# STM32H730xxQ register map
File version: 1.0
Registers are 32-bit, read-write, reset 0x0 unless marked. A register's access mark holds for its fields unless they carry their own. Offsets are from the block's base; [hi:lo] are bit positions.

## PWR — Power Control
Base 0x58024800
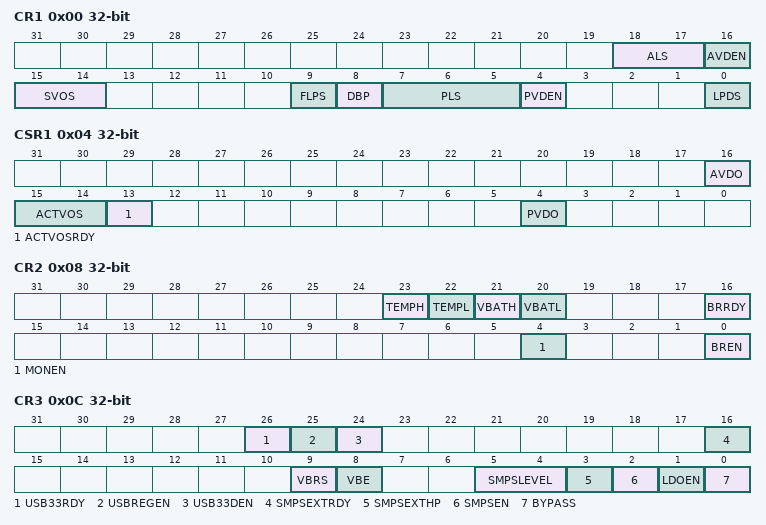
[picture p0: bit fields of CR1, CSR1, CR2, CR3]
0x00 CR1 — PWR power control register 1
  [18:17] ALS — Analog Voltage Detector level selection
    0=AVDLEVEL_0 (Analog Voltage threshold detected by AVD 1.7 V); 1=AVDLEVEL_1 (Analog Voltage threshold detected by AVD 2.1 V); 2=AVDLEVEL_2 (Analog Voltage threshold detected by AVD 2.5 V); 3=AVDLEVEL_3 (Analog Voltage threshold detected by AVD 2.8 V)
  [16] AVDEN — Analog Voltage Detector Enable
  [15:14] SVOS — System STOP mode Voltage Scaling selection
    3=SCALE3 (Select voltage scale 3 when system enters STOP mode); 2=SCALE4 (Select voltage scale 4 when system enters STOP mode); 1=SCALE5 (Select voltage scale 5 when system enters STOP mode)
  [9] FLPS — Flash low power mode in DSTOP
  [8] DBP — Disable Back-up domain Protection
  [7:5] PLS — Programmable Voltage Detector level selection
    0=PVDLEVEL_0 (Voltage threshold detected by PVD 1.95 V); 1=PVDLEVEL_1 (Voltage threshold detected by PVD 2.1 V); 2=PVDLEVEL_2 (Voltage threshold detected by PVD 2.25 V); 3=PVDLEVEL_3 (Voltage threshold detected by PVD 2.4 V); 4=PVDLEVEL_4 (Voltage threshold detected by PVD 2.55 V); 5=PVDLEVEL_5 (Voltage threshold detected by PVD 2.7 V); 6=PVDLEVEL_6 (Voltage threshold detected by PVD 2.85 V); 7=PVDLEVEL_7 (External voltage level on PVD_IN pin, compared to internal VREFINT level.)
  [4] PVDEN — Programmable Voltage detector enable
  [0] LPDS — Low Power Deepsleep with SVOS3
    0=MAIN (Voltage Regulator in main mode during deepsleep mode); 1=LOW_POWER (Voltage Regulator in low-power mode during deepsleep mode)
0x04 CSR1 — PWR power control status register 1
  [16] AVDO — Analog Voltage Detect Output
  [15:14] ACTVOS — Current actual used VOS for VDD11 Voltage Scaling
  [13] ACTVOSRDY — Ready bit for current actual used VOS for VDD11 Voltage Scaling
  [4] PVDO — Programmable Voltage Detect Output
0x08 CR2 — PWR power control register 2
  [23] TEMPH — Monitored temperature level above high threshold
  [22] TEMPL — Monitored temperature level above low threshold
  [21] VBATH — Monitored VBAT level above high threshold
  [20] VBATL — Monitored VBAT level above low threshold
  [16] BRRDY — Backup regulator ready
  [4] MONEN — VBAT and temperature monitoring enable
  [0] BREN — Backup regulator enable
0x0C CR3 — PWR power control register 3
  [26] USB33RDY — USB supply ready
  [25] USBREGEN — USB regulator enable
  [24] USB33DEN — VDD33_USB voltage level detector enable
  [16] SMPSEXTRDY — SMPS External supply ready
  [9] VBRS — VBAT charging resistor selection
    0=CHARG_RESISTOR_5K (Charge the Battery through a 5 kO resistor); 1=CHARGRESISTOR_1_5K (Charge the Battery through a 1.5 kO resistor)
  [8] VBE — VBAT charging enable
  [5:4] SMPSLEVEL — SMPS output Voltage
  [3] SMPSEXTHP — SMPS forced ON and in High Power MR mode
  [2] SMPSEN — SMPS Enable
  [1] LDOEN — Low Drop Output regulator enable
  [0] BYPASS — Power Management Unit bypass
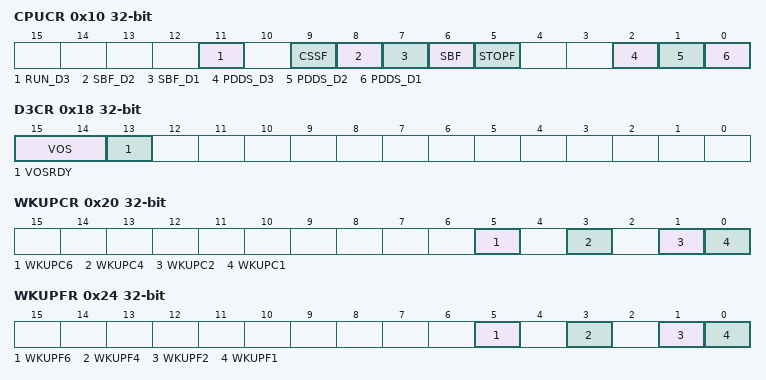
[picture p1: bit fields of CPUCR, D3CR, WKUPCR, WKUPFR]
0x10 CPUCR — PWR CPU control register
  [11] RUN_D3 — Keep system D3 domain in RUN mode regardless of the CPU sub-systems modes
  [9] CSSF — Clear D1 domain CPU1 STANDBY, STOP and HOLD flags
  [8] SBF_D2 — D2 domain DSTANDBY Flag
  [7] SBF_D1 — D1 domain DSTANDBY Flag
  [6] SBF — System STANDBY Flag
  [5] STOPF — STOP Flag
  [2] PDDS_D3 — System D3 domain Power Down Deepsleep
    0=D3STOP (Enter D3 domain to Stop mode when the CPU enters deepsleep); 1=D3STANDBY (Enter D3 domain to Standby mode when the CPU enters deepsleep)
  [1] PDDS_D2 — D2 domain Power Down Deepsleep
    0=D2STOP (Enter D2 domain to Stop mode when the CPU enters deepsleep); 1=D2STANDBY (Enter D2 domain to Standby mode when the CPU enters deepsleep)
  [0] PDDS_D1 — D1 domain Power Down Deepsleep selection
    0=D1STOP (Enter D1 domain to Stop mode when the CPU enters deepsleep); 1=D1STANDBY (Enter D1 domain to Standby mode when the CPU enters deepsleep)
0x18 D3CR — PWR D3 domain control register
  [15:14] VOS — Voltage Scaling selection according performance
  [13] VOSRDY — VOS Ready bit for VDD11 Voltage Scaling output selection
0x20 WKUPCR — PWR wakeup clear register
  [5] WKUPC6 — Clear Wakeup Pin Flag 6
  [3] WKUPC4 — Clear Wakeup Pin Flag 4
  [1] WKUPC2 — Clear Wakeup Pin Flag 2
  [0] WKUPC1 — Clear Wakeup Pin Flag 1
0x24 WKUPFR — PWR wakeup flag register
  [5] WKUPF6 — Wakeup Pin Flag 6
  [3] WKUPF4 — Wakeup Pin Flag 4
  [1] WKUPF2 — Wakeup Pin Flag 2
  [0] WKUPF1 — Wakeup Pin Flag 1
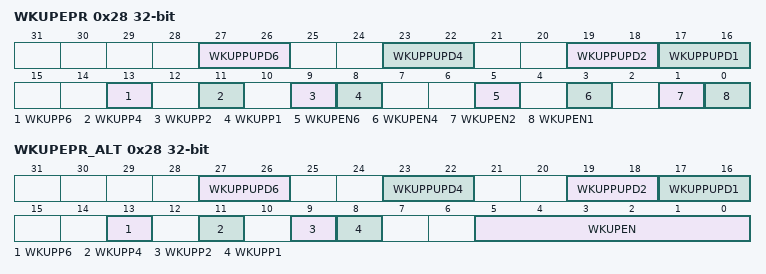
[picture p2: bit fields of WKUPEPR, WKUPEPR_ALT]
0x28 WKUPEPR — PWR wakeup enable and polarity register
  [27:26] WKUPPUPD6 — Wakeup Pin pull configuration for WKUP6
  [23:22] WKUPPUPD4 — Wakeup Pin pull configuration for WKUP4
  [19:18] WKUPPUPD2 — Wakeup Pin pull configuration for WKUP2
  [17:16] WKUPPUPD1 — Wakeup Pin pull configuration for WKUP1
  [13] WKUPP6 — Wakeup Pin Polarity for WKUP6
  [11] WKUPP4 — Wakeup Pin Polarity for WKUP4
  [9] WKUPP2 — Wakeup Pin Polarity for WKUP2
  [8] WKUPP1 — Wakeup Pin Polarity for WKUP1
  [5] WKUPEN6 — Enable Wakeup Pin WKUP6
  [3] WKUPEN4 — Enable Wakeup Pin WKUP4
  [1] WKUPEN2 — Enable Wakeup Pin WKUP2
  [0] WKUPEN1 — Enable Wakeup Pin WKUP1
0x28 WKUPEPR_ALT (alternate view of WKUPEPR) — PWR wakeup enable and polarity register
  [27:26] WKUPPUPD6 — Wakeup Pin pull configuration for WKUP6
  [23:22] WKUPPUPD4 — Wakeup Pin pull configuration for WKUP4
  [19:18] WKUPPUPD2 — Wakeup Pin pull configuration for WKUP2
  [17:16] WKUPPUPD1 — Wakeup Pin pull configuration for WKUP1
  [13] WKUPP6 — Wakeup Pin Polarity for WKUP6
  [11] WKUPP4 — Wakeup Pin Polarity for WKUP4
  [9] WKUPP2 — Wakeup Pin Polarity for WKUP2
  [8] WKUPP1 — Wakeup Pin Polarity for WKUP1
  [5:0] WKUPEN — Enable all Wakeup Pin
